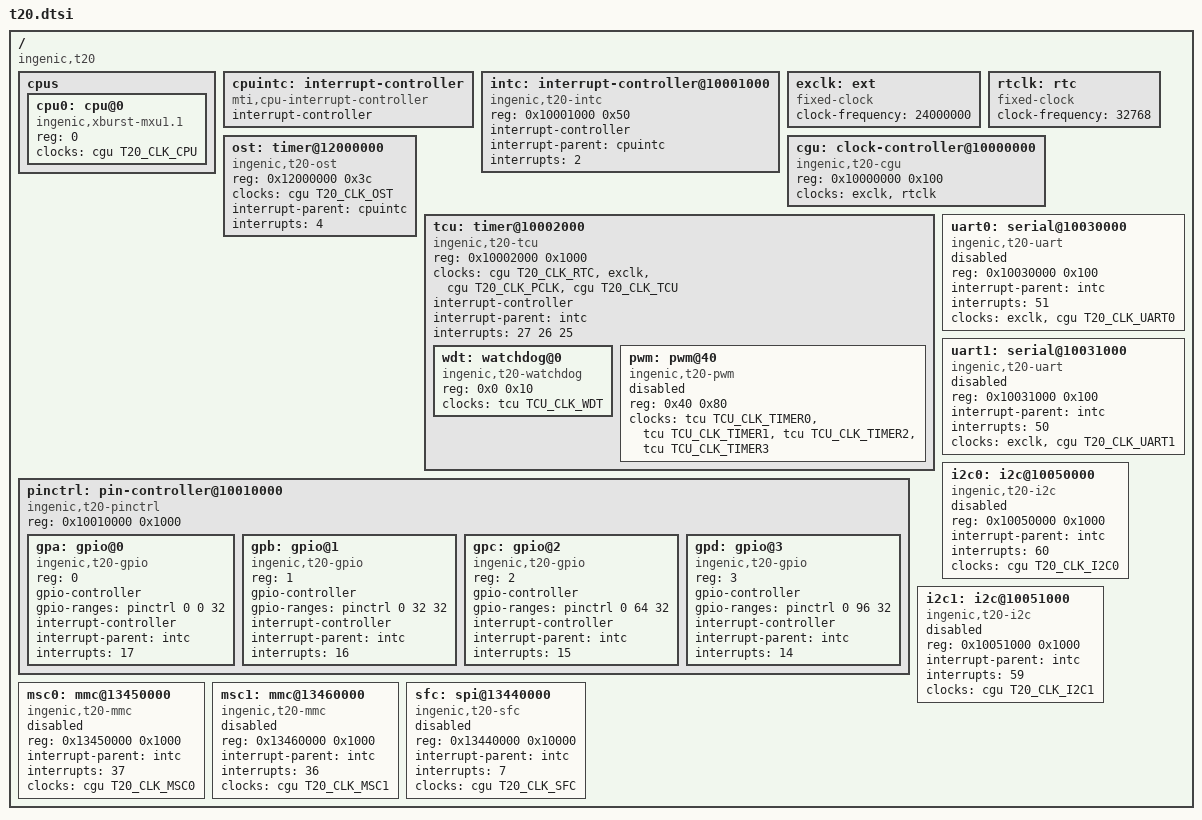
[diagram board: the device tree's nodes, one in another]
// SPDX-License-Identifier: GPL-2.0
/*
 * Ingenic T20. Addresses, interrupts and clocks from Ingenic's 3.10.14 tree
 * (arch/mips/xburst/soc-t20), laid out like the mainline X1000 and
 * gtxaspec's T31 device trees.
 */
#include <dt-bindings/clock/ingenic,tcu.h>
#include <dt-bindings/clock/ingenic,t20-cgu.h>

/ {
	#address-cells = <1>;
	#size-cells = <1>;
	compatible = "ingenic,t20";

	cpus {
		#address-cells = <1>;
		#size-cells = <0>;

		cpu0: cpu@0 {
			device_type = "cpu";
			compatible = "ingenic,xburst-mxu1.1";
			reg = <0>;

			clocks = <&cgu T20_CLK_CPU>;
			clock-names = "cpu";
		};
	};

	cpuintc: interrupt-controller {
		#address-cells = <0>;
		#interrupt-cells = <1>;
		interrupt-controller;
		compatible = "mti,cpu-interrupt-controller";
	};

	/* Two banks of 32 (vendor soc/irq.h) on CPU IP2 */
	intc: interrupt-controller@10001000 {
		compatible = "ingenic,t20-intc", "ingenic,jz4780-intc";
		reg = <0x10001000 0x50>;

		interrupt-controller;
		#interrupt-cells = <1>;

		interrupt-parent = <&cpuintc>;
		interrupts = <2>;
	};

	exclk: ext {
		compatible = "fixed-clock";
		#clock-cells = <0>;
		clock-frequency = <24000000>;
	};

	rtclk: rtc {
		compatible = "fixed-clock";
		#clock-cells = <0>;
		clock-frequency = <32768>;
	};

	cgu: clock-controller@10000000 {
		compatible = "ingenic,t20-cgu", "simple-mfd";
		reg = <0x10000000 0x100>;
		#address-cells = <1>;
		#size-cells = <1>;
		ranges = <0x0 0x10000000 0x100>;

		#clock-cells = <1>;

		clocks = <&exclk>, <&rtclk>;
		clock-names = "ext", "rtc";
	};

	/*
	 * System OST: same block as the X1000's. The vendor kernel takes its
	 * interrupt straight from CPU IP4 (soc-t20/common/irq.c).
	 */
	ost: timer@12000000 {
		compatible = "ingenic,t20-ost", "ingenic,x1000-ost";
		reg = <0x12000000 0x3c>;

		#clock-cells = <1>;

		clocks = <&cgu T20_CLK_OST>;
		clock-names = "ost";

		interrupt-parent = <&cpuintc>;
		interrupts = <4>;
	};

	tcu: timer@10002000 {
		compatible = "ingenic,t20-tcu", "ingenic,x1000-tcu", "simple-mfd";
		reg = <0x10002000 0x1000>;
		#address-cells = <1>;
		#size-cells = <1>;
		ranges = <0x0 0x10002000 0x1000>;

		#clock-cells = <1>;

		clocks = <&cgu T20_CLK_RTC>,
			 <&exclk>,
			 <&cgu T20_CLK_PCLK>,
			 <&cgu T20_CLK_TCU>;
		clock-names = "rtc", "ext", "pclk", "tcu";

		interrupt-controller;
		#interrupt-cells = <1>;

		interrupt-parent = <&intc>;
		interrupts = <27 26 25>;

		wdt: watchdog@0 {
			compatible = "ingenic,t20-watchdog", "ingenic,jz4780-watchdog";
			reg = <0x0 0x10>;

			clocks = <&tcu TCU_CLK_WDT>;
			clock-names = "wdt";
		};

		pwm: pwm@40 {
			compatible = "ingenic,t20-pwm", "ingenic,jz4740-pwm";
			reg = <0x40 0x80>;

			#pwm-cells = <3>;

			clocks = <&tcu TCU_CLK_TIMER0>, <&tcu TCU_CLK_TIMER1>,
				 <&tcu TCU_CLK_TIMER2>, <&tcu TCU_CLK_TIMER3>;
			clock-names = "timer0", "timer1", "timer2", "timer3";

			status = "disabled";
		};
	};

	/* Ports A to D, 0x100 apart; GPIO n is port n / 32, pin n % 32 */
	pinctrl: pin-controller@10010000 {
		compatible = "ingenic,t20-pinctrl";
		reg = <0x10010000 0x1000>;

		#address-cells = <1>;
		#size-cells = <0>;

		gpa: gpio@0 {
			compatible = "ingenic,t20-gpio";
			reg = <0>;

			gpio-controller;
			gpio-ranges = <&pinctrl 0 0 32>;
			#gpio-cells = <2>;

			interrupt-controller;
			#interrupt-cells = <2>;

			interrupt-parent = <&intc>;
			interrupts = <17>;
		};

		gpb: gpio@1 {
			compatible = "ingenic,t20-gpio";
			reg = <1>;

			gpio-controller;
			gpio-ranges = <&pinctrl 0 32 32>;
			#gpio-cells = <2>;

			interrupt-controller;
			#interrupt-cells = <2>;

			interrupt-parent = <&intc>;
			interrupts = <16>;
		};

		gpc: gpio@2 {
			compatible = "ingenic,t20-gpio";
			reg = <2>;

			gpio-controller;
			gpio-ranges = <&pinctrl 0 64 32>;
			#gpio-cells = <2>;

			interrupt-controller;
			#interrupt-cells = <2>;

			interrupt-parent = <&intc>;
			interrupts = <15>;
		};

		gpd: gpio@3 {
			compatible = "ingenic,t20-gpio";
			reg = <3>;

			gpio-controller;
			gpio-ranges = <&pinctrl 0 96 32>;
			#gpio-cells = <2>;

			interrupt-controller;
			#interrupt-cells = <2>;

			interrupt-parent = <&intc>;
			interrupts = <14>;
		};
	};

	uart0: serial@10030000 {
		compatible = "ingenic,t20-uart", "ingenic,x1000-uart";
		reg = <0x10030000 0x100>;

		interrupt-parent = <&intc>;
		interrupts = <51>;

		clocks = <&exclk>, <&cgu T20_CLK_UART0>;
		clock-names = "baud", "module";

		status = "disabled";
	};

	uart1: serial@10031000 {
		compatible = "ingenic,t20-uart", "ingenic,x1000-uart";
		reg = <0x10031000 0x100>;

		interrupt-parent = <&intc>;
		interrupts = <50>;

		clocks = <&exclk>, <&cgu T20_CLK_UART1>;
		clock-names = "baud", "module";

		status = "disabled";
	};

	i2c0: i2c@10050000 {
		compatible = "ingenic,t20-i2c", "ingenic,x1000-i2c";
		reg = <0x10050000 0x1000>;
		#address-cells = <1>;
		#size-cells = <0>;

		interrupt-parent = <&intc>;
		interrupts = <60>;

		clocks = <&cgu T20_CLK_I2C0>;

		status = "disabled";
	};

	i2c1: i2c@10051000 {
		compatible = "ingenic,t20-i2c", "ingenic,x1000-i2c";
		reg = <0x10051000 0x1000>;
		#address-cells = <1>;
		#size-cells = <0>;

		interrupt-parent = <&intc>;
		interrupts = <59>;

		clocks = <&cgu T20_CLK_I2C1>;

		status = "disabled";
	};

	/*
	 * MSC0 and MSC1 run without DMA for now (the PDMA controller is not
	 * described yet); the driver falls back to PIO.
	 */
	msc0: mmc@13450000 {
		compatible = "ingenic,t20-mmc", "ingenic,x1000-mmc";
		reg = <0x13450000 0x1000>;

		interrupt-parent = <&intc>;
		interrupts = <37>;

		clocks = <&cgu T20_CLK_MSC0>;
		clock-names = "mmc";

		status = "disabled";
	};

	msc1: mmc@13460000 {
		compatible = "ingenic,t20-mmc", "ingenic,x1000-mmc";
		reg = <0x13460000 0x1000>;

		interrupt-parent = <&intc>;
		interrupts = <36>;

		clocks = <&cgu T20_CLK_MSC1>;
		clock-names = "mmc";

		status = "disabled";
	};

	sfc: spi@13440000 {
		compatible = "ingenic,t20-sfc", "ingenic,x1000-sfc";
		reg = <0x13440000 0x10000>;

		interrupt-parent = <&intc>;
		interrupts = <7>;

		clocks = <&cgu T20_CLK_SFC>;
		clock-names = "sfc";

		#address-cells = <1>;
		#size-cells = <0>;

		status = "disabled";
	};
};
